# PIC32CX5109BZ31032 device description
Architecture: CORTEX-M4; Family: PIC32CX; Series: PIC32CXBZ31
Registers are 32-bit, read-write, reset 0x0 unless marked. A register's access mark holds for its fields unless they carry their own. Offsets are from the block's base; [hi:lo] are bit positions; {n}, {i} and the like mark numbered series; 'fields as' and 'values as' point back to an identical list; <NAME> marks a mode.

## DMAC_DESCRIPTOR — Direct Memory Access Controller
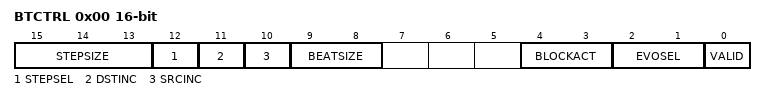
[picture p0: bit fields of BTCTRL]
0x00 BTCTRL 16-bit — Block Transfer Control
  [15:13] STEPSIZE — Address Increment Step Size
    0=Next ADDR = ADDR + (1<<BEATSIZE) * 1; 1=X2 (Next ADDR = ADDR + (1<<BEATSIZE) * 2); 2=X4 (Next ADDR = ADDR + (1<<BEATSIZE) * 4); 3=X8 (Next ADDR = ADDR + (1<<BEATSIZE) * 8); 4=X16 (Next ADDR = ADDR + (1<<BEATSIZE) * 16); 5=X32 (Next ADDR = ADDR + (1<<BEATSIZE) * 32); 6=X64 (Next ADDR = ADDR + (1<<BEATSIZE) * 64); 7=X128 (Next ADDR = ADDR + (1<<BEATSIZE) * 128)
  [12] STEPSEL — Step Selection
    0=DST (Step size settings apply to the destination address); 1=SRC (Step size settings apply to the source address)
  [11] DSTINC — Destination Address Increment Enable
  [10] SRCINC — Source Address Increment Enable
  [9:8] BEATSIZE
    0=BYTE (8-bit bus transfer); 1=HWORD (16-bit bus transfer); 2=WORD (32-bit bus transfer)
  [4:3] BLOCKACT — Block Action
    0=NOACT (Channel will be disabled if it is the last block transfer in the transaction); 1=INT (Channel will be disabled if it is the last block transfer in the transaction and block interrupt); 2=SUSPEND (Channel suspend operation is completed); 3=BOTH (Both channel suspend operation and block interrupt)
  [2:1] EVOSEL — Block Event Output Selection
    0=DISABLE (Event generation disabled); 1=BLOCK (Block event strobe); 3=BURST (Burst event strobe)
  [0] VALID — Descriptor Valid
0x02 BTCNT 16-bit — Block Transfer Count
0x04 SRCADDR — Block Transfer Source Address
  [31:0] SRCADDR — Transfer Source Address
0x08 DSTADDR reset not defined — Block Transfer Destination Address
  [31:0] CHKINIT <CRC> — CRC Checksum Initial Value
  [31:0] DSTADDR <DEFAULT> — Transfer Destination Address
0x0C DESCADDR reset not defined — Next Descriptor Address

## DMT — Dead Man Timer
Instances: DMT 0x44000E00
0x00 DMTCON
  [15] ON
0x04 DMTCONCLR — Bit clear register
0x08 DMTCONSET — Bit set register
0x0C DMTCONINV — Bit invert register
0x10 DMTPRECLR
  [15:8] STEP1
0x14 DMTPRECLRCLR — Bit clear register
0x18 DMTPRECLRSET — Bit set register
0x1C DMTPRECLRINV — Bit invert register
0x20 DMTCLR
  [7:0] STEP2
0x24 DMTCLRCLR — Bit clear register
0x28 DMTCLRSET — Bit set register
0x2C DMTCLRINV — Bit invert register
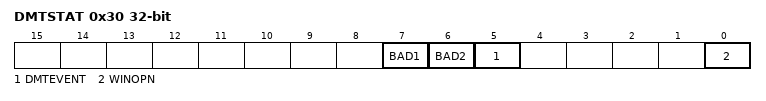
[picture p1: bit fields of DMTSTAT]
0x30 DMTSTAT
  [7] BAD1, [6] BAD2, [5] DMTEVENT, [0] WINOPN
0x34 DMTSTATCLR — Bit clear register
0x38 DMTSTATSET — Bit set register
0x3C DMTSTATINV — Bit invert register
0x40 DMTCNT ro
  [31:0] COUNTER
0x44 DMTCNTCLR — Bit clear register
0x48 DMTCNTSET — Bit set register
0x4C DMTCNTINV — Bit invert register
0x50 DMTHOLDREG ro
  [15:0] UPRCNT
0x54 DMTHOLDREGCLR — Bit clear register
0x58 DMTHOLDREGSET — Bit set register
0x5C DMTHOLDREGINV — Bit invert register
0x60 DMTPSCNT ro
  [31:0] PSCNT
0x64 DMTPSCNTCLR — Bit clear register
0x68 DMTPSCNTSET — Bit set register
0x6C DMTPSCNTINV — Bit invert register
0x70 DMTPSINTV ro
  [31:0] PSINTV
0x74 DMTPSINTVCLR — Bit clear register
0x78 DMTPSINTVSET — Bit set register
0x7C DMTPSINTVINV — Bit invert register

## DSCON
Instances: DSCON 0x42011000
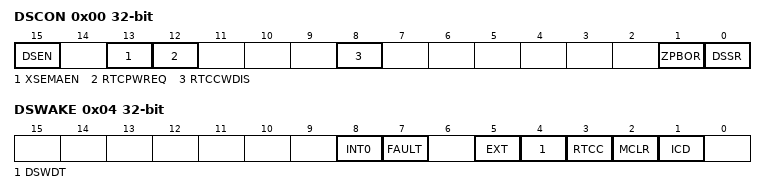
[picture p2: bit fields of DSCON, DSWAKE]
0x00 DSCON
  [15] DSEN, [13] XSEMAEN, [12] RTCPWREQ, [8] RTCCWDIS, [1] ZPBOR, [0] DSSR
0x04 DSWAKE
  [8] INT0, [7] FAULT, [5] EXT, [4] DSWDT, [3] RTCC, [2] MCLR, [1] ICD
0x08 DSSEMA1
  [31:0] DSSEMA
0x10 DSXSEMA1
  [31:0] DSXSEMA

## EIC — External Interrupt Controller
Instances: EIC 0x40000800
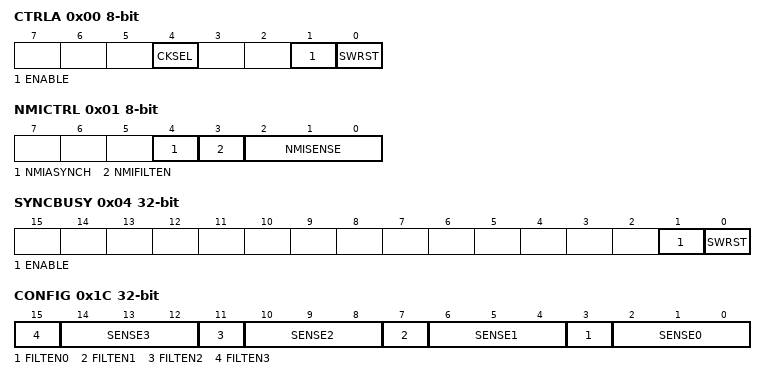
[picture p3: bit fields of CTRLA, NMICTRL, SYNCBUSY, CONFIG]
0x00 CTRLA 8-bit — Control A
  [4] CKSEL — Clock Selection
    0=CLK_GCLK (Clocked by GCLK); 1=32KHZ_LPCLK (Clocked by LPCLK)
  [1] ENABLE
  [0] SWRST — Software Reset
0x01 NMICTRL 8-bit — Non-Maskable Interrupt Control
  [4] NMIASYNCH — Asynchronous Edge Detection Mode
    0=SYNC (Edge detection is clock synchronously operated); 1=ASYNC (Edge detection is clock asynchronously operated)
  [3] NMIFILTEN — Non-Maskable Interrupt Filter Enable
  [2:0] NMISENSE — Non-Maskable Interrupt Sense Configuration
    0=NONE (No detection); 1=RISE (Rising-edge detection); 2=FALL (Falling-edge detection); 3=BOTH (Both-edges detection); 4=HIGH (High-level detection); 5=LOW (Low-level detection)
0x02 NMIFLAG 16-bit (atomic clear) — Non-Maskable Interrupt Flag Status and Clear
  [0] NMI — Non-Maskable Interrupt
0x04 SYNCBUSY ro — Synchronization Busy
  [1] ENABLE — Enable Synchronization Busy Status
  [0] SWRST — Software Reset Synchronization Busy Status
0x08 EVCTRL — Event Control
  [3:0] EXTINTEO — External Interrupt Event Output Enable
0x0C INTENCLR (atomic clear) — Interrupt Enable Clear
  [3:0] EXTINT — External Interrupt Enable
0x10 INTENSET (atomic set) — Interrupt Enable Set
  [3:0] EXTINT — External Interrupt Enable
0x14 INTFLAG (atomic clear) — Interrupt Flag Status and Clear
  [3:0] EXTINT — External Interrupt
0x18 ASYNCH — External Interrupt Asynchronous Mode
  [3:0] ASYNCH — Asynchronous Edge Detection Mode
    values as NMICTRL.NMIASYNCH
0x1C CONFIG — External Interrupt Sense Configuration
  [4n+3] FILTEN{n} (n=0..3) — Filter Enable {n}
  [4n+2:4n] SENSE{n} (n=0..3) — Input Sense Configuration {n}
    0=NONE (No detection); 1=RISE (Rising edge detection); 2=FALL (Falling edge detection); 3=BOTH (Both edges detection); 4=HIGH (High level detection); 5=LOW (Low level detection)
0x30 DEBOUNCEN — Debouncer Enable
  [3:0] DEBOUNCEN
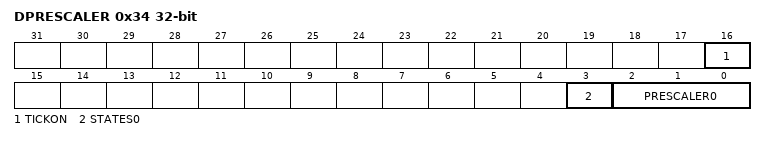
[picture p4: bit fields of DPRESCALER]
0x34 DPRESCALER — Debouncer Prescaler
  [16] TICKON — Pin Sampler frequency selection
    0=CLK_GCLK_EIC (Clocked by GCLK); 1=CLK_LFREQ (Clocked by Low Frequency Clock)
  [3] STATES0 — Debouncer number of states
    0=LFREQ3 (3 low frequency samples); 1=LFREQ7 (7 low frequency samples)
  [2:0] PRESCALER0 — Debouncer Prescaler
    0=DIV2 (EIC clock divided by 2); 1=DIV4 (EIC clock divided by 4); 2=DIV8 (EIC clock divided by 8); 3=DIV16 (EIC clock divided by 16); 4=DIV32 (EIC clock divided by 32); 5=DIV64 (EIC clock divided by 64); 6=DIV128 (EIC clock divided by 128); 7=DIV256 (EIC clock divided by 256)
0x38 PINSTATE ro
  [3:0] PINSTATE
